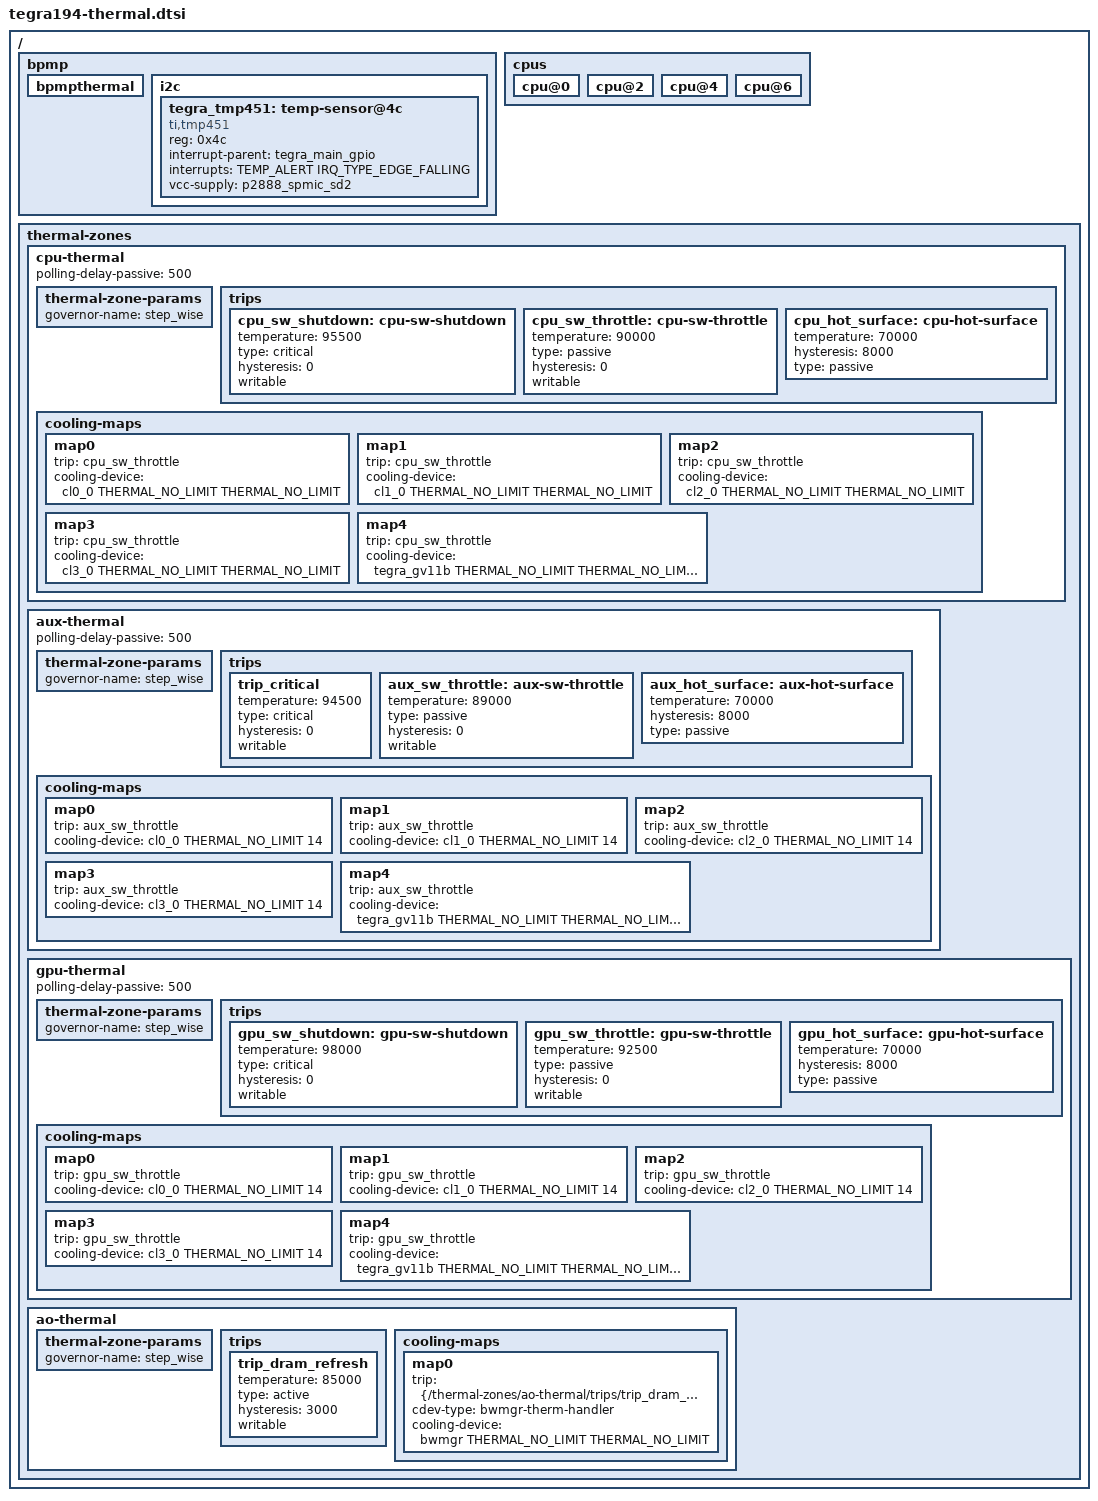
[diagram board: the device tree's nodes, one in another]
/*
 * Copyright (c) 2017-2022, NVIDIA CORPORATION.  All rights reserved.
 *
 * This program is free software; you can redistribute it and/or modify it
 * under the terms and conditions of the GNU General Public License,
 * version 2, as published by the Free Software Foundation.
 *
 * This program is distributed in the hope it will be useful, but WITHOUT
 * ANY WARRANTY; without even the implied warranty of MERCHANTABILITY or
 * FITNESS FOR A PARTICULAR PURPOSE.  See the GNU General Public License for
 * more details.
 *
 * You should have received a copy of the GNU General Public License
 * along with this program.  If not, see <http://www.gnu.org/licenses/>.
 */

#include <dt-bindings/interrupt-controller/arm-gic.h>
#include <dt-bindings/gpio/tegra194-gpio.h>
#include <dt-bindings/thermal/thermal.h>
#include "tegra194-balanced-throttle.dtsi"
#include "tegra194-pwm-fan.dtsi"
/* THERMAL gpio definitions */
#define TEMP_ALERT TEGRA194_MAIN_GPIO(H, 2)

/ {
	bpmp {
		bpmpthermal {
			status = "okay";
		};
	};

	bpmp {
		i2c {
			tegra_tmp451: temp-sensor@4c {
				compatible = "ti,tmp451";
				reg = <0x4c>;
				status = "okay";

				interrupt-parent = <&tegra_main_gpio>;
				interrupts = <TEMP_ALERT IRQ_TYPE_EDGE_FALLING>;

				vcc-supply = <&p2888_spmic_sd2>;

				#thermal-sensor-cells = <1>;
			};
		};
	};

	cpus {
		cpu@0 {
			#cooling-cells = <2>;
		};

		cpu@2 {
			#cooling-cells = <2>;
		};

		cpu@4 {
			#cooling-cells = <2>;
		};

		cpu@6 {
			#cooling-cells = <2>;
		};
	};

	thermal-zones {
		status = "okay";

		cpu-thermal {
			status = "okay";
			polling-delay-passive = <500>;

			thermal-zone-params {
				governor-name = "step_wise";
			};

			trips {
				cpu_sw_shutdown: cpu-sw-shutdown {
					temperature = <95500>;
					type = "critical";
					hysteresis = <0>;
					writable;
				};

				cpu_sw_throttle: cpu-sw-throttle {
					temperature = <90000>;
					type = "passive";
					hysteresis = <0>;
					writable;
				};

				cpu_hot_surface: cpu-hot-surface {
					temperature = <70000>;
					hysteresis = <8000>;
					type = "passive";
				};
			};

			cooling-maps {
				map0 {
					trip = <&cpu_sw_throttle>;
					cooling-device = <&cl0_0 THERMAL_NO_LIMIT THERMAL_NO_LIMIT>;
				};
				map1 {
					trip = <&cpu_sw_throttle>;
					cooling-device = <&cl1_0 THERMAL_NO_LIMIT THERMAL_NO_LIMIT>;
				};
				map2 {
					trip = <&cpu_sw_throttle>;
					cooling-device = <&cl2_0 THERMAL_NO_LIMIT THERMAL_NO_LIMIT>;
				};
				map3 {
					trip = <&cpu_sw_throttle>;
					cooling-device = <&cl3_0 THERMAL_NO_LIMIT THERMAL_NO_LIMIT>;
				};
				map4 {
					trip = <&cpu_sw_throttle>;
					cooling-device = <&tegra_gv11b THERMAL_NO_LIMIT THERMAL_NO_LIMIT>;
				};
			};
		};

		aux-thermal {
			status = "okay";
			polling-delay-passive = <500>;

			thermal-zone-params {
				governor-name = "step_wise";
			};

			trips {
				trip_critical {
					temperature = <94500>;
					type = "critical";
					hysteresis = <0>;
					writable;
				};

				aux_sw_throttle: aux-sw-throttle {
					temperature = <89000>;
					type = "passive";
					hysteresis = <0>;
					writable;
				};

				aux_hot_surface: aux-hot-surface {
					temperature = <70000>;
					hysteresis = <8000>;
					type = "passive";
				};
			};

			cooling-maps {
				map0 {
					trip = <&aux_sw_throttle>;
					cooling-device = <&cl0_0 THERMAL_NO_LIMIT 14>;
				};
				map1 {
					trip = <&aux_sw_throttle>;
					cooling-device = <&cl1_0 THERMAL_NO_LIMIT 14>;
				};
				map2 {
					trip = <&aux_sw_throttle>;
					cooling-device = <&cl2_0 THERMAL_NO_LIMIT 14>;
				};
				map3 {
					trip = <&aux_sw_throttle>;
					cooling-device = <&cl3_0 THERMAL_NO_LIMIT 14>;
				};
				map4 {
					trip = <&aux_sw_throttle>;
					cooling-device = <&tegra_gv11b THERMAL_NO_LIMIT THERMAL_NO_LIMIT>;
				};
			};
		};

		gpu-thermal {
			status = "okay";
			polling-delay-passive = <500>;

			thermal-zone-params {
				governor-name = "step_wise";
			};

			trips {
				gpu_sw_shutdown: gpu-sw-shutdown {
					temperature = <98000>;
					type = "critical";
					hysteresis = <0>;
					writable;
				};

				gpu_sw_throttle: gpu-sw-throttle {
					temperature = <92500>;
					type = "passive";
					hysteresis = <0>;
					writable;
				};

				gpu_hot_surface: gpu-hot-surface {
					temperature = <70000>;
					hysteresis = <8000>;
					type = "passive";
				};
			};

			cooling-maps {
				map0 {
					trip = <&gpu_sw_throttle>;
					cooling-device = <&cl0_0 THERMAL_NO_LIMIT 14>;
				};
				map1 {
					trip = <&gpu_sw_throttle>;
					cooling-device = <&cl1_0 THERMAL_NO_LIMIT 14>;
				};
				map2 {
					trip = <&gpu_sw_throttle>;
					cooling-device = <&cl2_0 THERMAL_NO_LIMIT 14>;
				};
				map3 {
					trip = <&gpu_sw_throttle>;
					cooling-device = <&cl3_0 THERMAL_NO_LIMIT 14>;
				};
				map4 {
					trip = <&gpu_sw_throttle>;
					cooling-device = <&tegra_gv11b THERMAL_NO_LIMIT THERMAL_NO_LIMIT>;
				};
			};
		};

		ao-thermal {
			status = "okay";

			thermal-zone-params {
				governor-name = "step_wise";
			};

			trips {
				trip_dram_refresh {
					temperature = <85000>;
					type = "active";
					hysteresis = <3000>;
					writable;
				};
			};
			cooling-maps {
				map0 {
					trip = <&{/thermal-zones/ao-thermal/trips/trip_dram_refresh}>;
					cdev-type = "bwmgr-therm-handler";
					cooling-device = <&bwmgr THERMAL_NO_LIMIT THERMAL_NO_LIMIT>;
				};
			};
		};

	};
};
